VERSION ""

NS_ :

BS_:

BU_: XXX

BO_ 85 CID_AAKJTR: 8 XXX
 SG_ sig_rjgekf : 40|1@1+ (1,0) [0|1] "" XXX
 SG_ sig_xjcfym : 56|8@1+ (1,0) [0|255] "" XXX

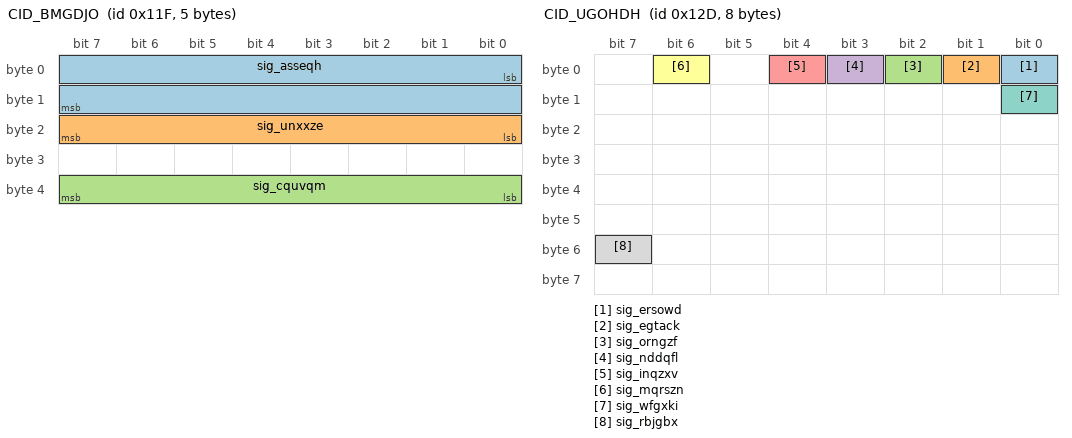
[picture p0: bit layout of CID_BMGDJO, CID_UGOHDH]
BO_ 287 CID_BMGDJO: 5 XXX
 SG_ sig_asseqh : 0|16@1- (0.1,0) [-450|450] "" XXX
 SG_ sig_unxxze : 16|8@1+ (4,0) [0|1020] "" XXX
 SG_ sig_cquvqm : 32|8@1+ (1,0) [0|255] "" XXX

BO_ 289 CID_QHFXJQ: 8 XXX
 SG_ sig_uldnjl : 0|12@1+ (1,0) [0|255] "" XXX

BO_ 301 CID_UGOHDH: 8 XXX
 SG_ sig_ersowd : 0|1@0+ (1,0) [0|1] "" XXX
 SG_ sig_egtack : 1|1@0+ (1,0) [0|1] "" XXX
 SG_ sig_orngzf : 2|1@0+ (1,0) [0|1] "" XXX
 SG_ sig_nddqfl : 3|1@0+ (1,0) [0|1] "" XXX
 SG_ sig_inqzxv : 4|1@0+ (1,0) [0|1] "" XXX
 SG_ sig_mqrszn : 6|1@0+ (1,0) [0|1] "" XXX
 SG_ sig_wfgxki : 8|1@0+ (1,0) [0|1] "" XXX
 SG_ sig_rbjgbx : 55|1@0+ (1,0) [0|1] "" XXX

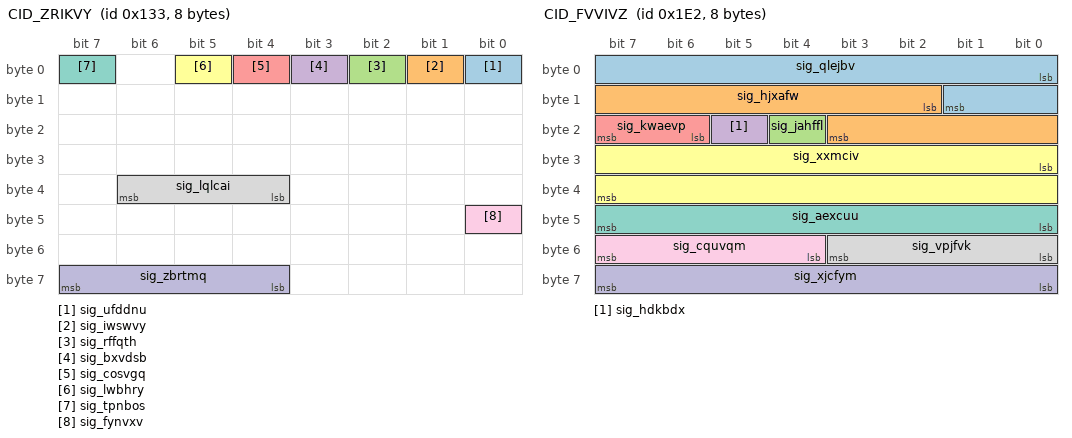
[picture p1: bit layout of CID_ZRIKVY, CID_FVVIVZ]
BO_ 307 CID_ZRIKVY: 8 XXX
 SG_ sig_ufddnu : 0|1@0+ (1,0) [0|1] "" XXX
 SG_ sig_iwswvy : 1|1@1+ (1,0) [0|1] "" XXX
 SG_ sig_rffqth : 2|1@1+ (1,0) [0|1] "" XXX
 SG_ sig_bxvdsb : 3|1@1+ (1,0) [0|1] "" XXX
 SG_ sig_cosvgq : 4|1@0+ (1,0) [0|1] "" XXX
 SG_ sig_lwbhry : 5|1@0+ (1,0) [0|1] "" XXX
 SG_ sig_tpnbos : 7|1@0+ (1,0) [0|1] "" XXX
 SG_ sig_lqlcai : 36|3@1+ (1,0) [0|7] "" XXX
 SG_ sig_fynvxv : 40|1@0+ (1,0) [0|1] "" XXX
 SG_ sig_zbrtmq : 63|4@0+ (1,0) [0|15] "" XXX

BO_ 482 CID_FVVIVZ: 8 XXX
 SG_ sig_qlejbv : 0|10@1- (0.01,0) [0|5] "" XXX
 SG_ sig_hjxafw : 10|10@1- (0.01,0) [-5|0] "" XXX
 SG_ sig_jahffl : 20|1@0+ (1,0) [0|1] "" XXX
 SG_ sig_hdkbdx : 21|1@0+ (1,0) [0|1] "" XXX
 SG_ sig_kwaevp : 22|2@1+ (1,0) [0|1] "" XXX
 SG_ sig_xxmciv : 24|16@1- (0.1,0) [-780|779.9] "" XXX
 SG_ sig_aexcuu : 47|8@0+ (1,0) [0|255] "" XXX
 SG_ sig_vpjfvk : 48|4@1+ (1,0) [0|15] "" XXX
 SG_ sig_cquvqm : 52|4@1+ (1,0) [0|15] "" XXX
 SG_ sig_xjcfym : 56|8@1+ (1,0) [0|255] "" XXX

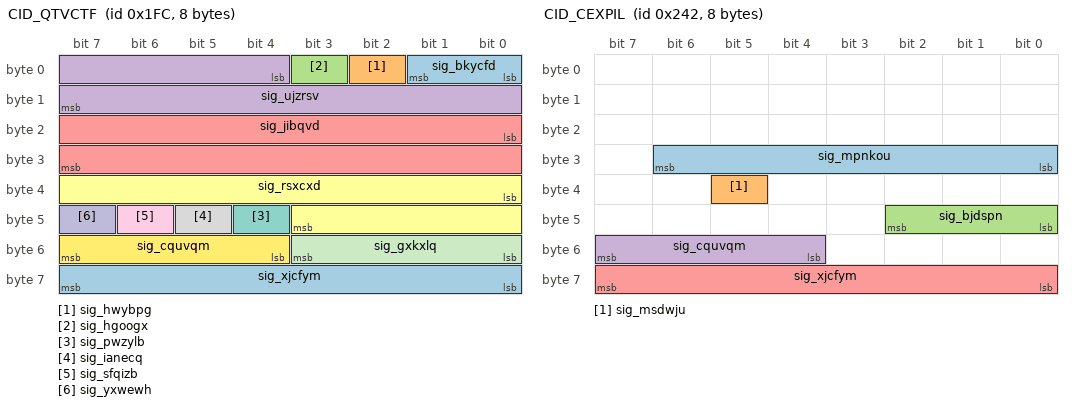
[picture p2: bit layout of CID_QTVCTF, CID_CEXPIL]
BO_ 508 CID_QTVCTF: 8 XXX
 SG_ sig_bkycfd : 0|2@1+ (1,0) [0|1] "" XXX
 SG_ sig_hwybpg : 2|1@1+ (1,0) [0|1] "" XXX
 SG_ sig_hgoogx : 3|1@0+ (1,0) [0|1] "" XXX
 SG_ sig_ujzrsv : 4|12@1- (1,0) [-2048|2047] "" XXX
 SG_ sig_jibqvd : 16|16@1- (0.1,0) [-780|779.9] "Deg" XXX
 SG_ sig_rsxcxd : 32|12@1- (1,0) [0|63] "" XXX
 SG_ sig_pwzylb : 44|1@0+ (1,0) [0|1] "" XXX
 SG_ sig_ianecq : 45|1@1+ (1,0) [0|255] "" XXX
 SG_ sig_sfqizb : 46|1@1+ (1,0) [0|1] "" XXX
 SG_ sig_yxwewh : 47|1@0+ (1,0) [0|3] "" XXX
 SG_ sig_gxkxlq : 48|4@1+ (1,0) [0|15] "" XXX
 SG_ sig_cquvqm : 52|4@1+ (1,0) [0|15] "" XXX
 SG_ sig_xjcfym : 56|8@1+ (1,0) [0|255] "" XXX

BO_ 578 CID_CEXPIL: 8 XXX
 SG_ sig_mpnkou : 30|7@0+ (1,0) [0|127] "" XXX
 SG_ sig_msdwju : 37|1@0+ (1,0) [0|1] "" XXX
 SG_ sig_bjdspn : 40|3@1+ (1,0) [0|7] "" XXX
 SG_ sig_cquvqm : 55|4@0+ (1,0) [0|15] "" XXX
 SG_ sig_xjcfym : 56|8@1+ (1,0) [0|255] "" XXX

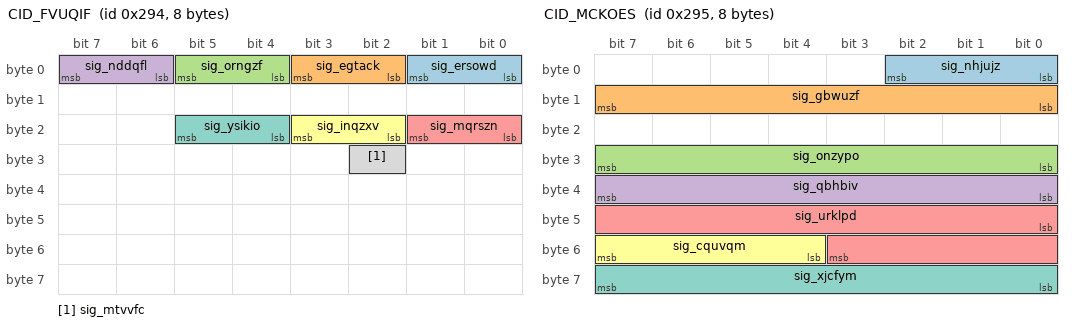
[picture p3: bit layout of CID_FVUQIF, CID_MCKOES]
BO_ 660 CID_FVUQIF: 8 XXX
 SG_ sig_ersowd : 1|2@0+ (1,0) [0|3] "" XXX
 SG_ sig_egtack : 3|2@0+ (1,0) [0|3] "" XXX
 SG_ sig_orngzf : 5|2@0+ (1,0) [0|3] "" XXX
 SG_ sig_nddqfl : 7|2@0+ (1,0) [0|3] "" XXX
 SG_ sig_mqrszn : 17|2@0+ (1,0) [0|3] "" XXX
 SG_ sig_inqzxv : 19|2@0+ (1,0) [0|3] "" XXX
 SG_ sig_ysikio : 21|2@0+ (1,0) [0|3] "" XXX
 SG_ sig_mtvvfc : 26|1@0+ (1,0) [0|1] "" XXX

BO_ 661 CID_MCKOES: 8 XXX
 SG_ sig_nhjujz : 2|3@0+ (1,0) [0|7] "" XXX
 SG_ sig_gbwuzf : 15|8@0+ (1,0) [0|255] "" XXX
 SG_ sig_onzypo : 31|8@0+ (1,0) [0|255] "" XXX
 SG_ sig_qbhbiv : 32|8@1+ (1,0) [0|255] "" XXX
 SG_ sig_urklpd : 40|12@1+ (1,0) [0|255] "" XXX
 SG_ sig_cquvqm : 52|4@1+ (1,0) [0|15] "" XXX
 SG_ sig_xjcfym : 63|8@0+ (1,0) [0|255] "" XXX

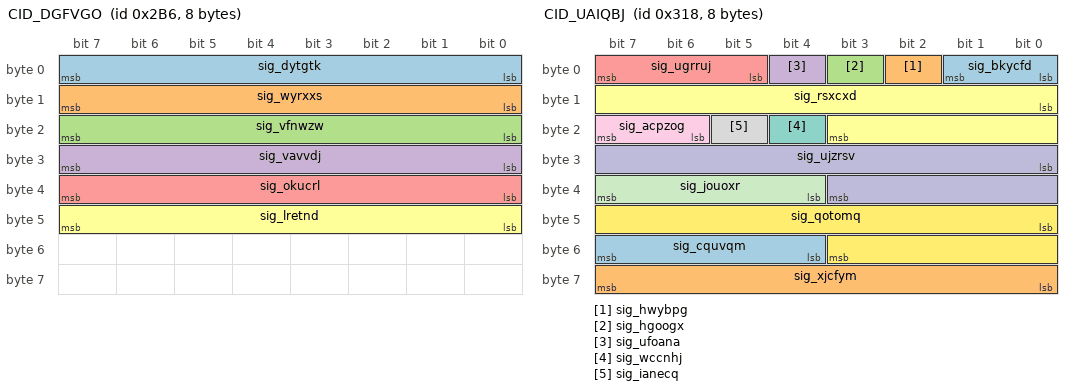
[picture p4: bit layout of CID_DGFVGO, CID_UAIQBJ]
BO_ 694 CID_DGFVGO: 8 XXX
 SG_ sig_dytgtk : 7|8@0+ (1,0) [0|255] "" XXX
 SG_ sig_wyrxxs : 15|8@0+ (1,0) [0|255] "" XXX
 SG_ sig_vfnwzw : 23|8@0+ (1,0) [0|255] "" XXX
 SG_ sig_vavvdj : 31|8@0+ (1,0) [0|255] "" XXX
 SG_ sig_okucrl : 39|8@0+ (1,0) [0|255] "" XXX
 SG_ sig_lretnd : 47|8@0+ (1,0) [0|255] "" XXX

BO_ 790 CID_OANJWA: 8 XXX
 SG_ sig_tidylo : 3|4@0+ (1,0) [0|1] "" XXX
 SG_ sig_bzvjkw : 4|2@1+ (1,0) [0|3] "" XXX
 SG_ sig_frfqzv : 6|2@1+ (1,0) [0|3] "" XXX
 SG_ sig_grirwu : 8|2@1+ (1,0) [0|3] "" XXX
 SG_ sig_tpqchs : 10|1@1+ (1,0) [0|1] "" XXX
 SG_ sig_fterep : 11|4@1+ (1,0) [0|1] "" XXX
 SG_ sig_aupjpc : 15|1@0+ (1,0) [0|1] "" XXX
 SG_ sig_xxmciv : 16|11@1- (1,0) [-1024|1023] "" XXX
 SG_ sig_jahffl : 27|1@1+ (1,0) [0|1] "" XXX
 SG_ sig_hdkbdx : 28|1@1+ (1,0) [0|3] "" XXX
 SG_ sig_ttxarj : 29|1@0+ (1,0) [0|1] "" XXX
 SG_ sig_nyqzlm : 30|1@0+ (1,0) [0|1] "" XXX
 SG_ sig_sapher : 31|1@0+ (1,0) [0|1] "" XXX
 SG_ sig_stewol : 32|2@1+ (1,0) [0|3] "" XXX
 SG_ sig_cqnbjs : 34|2@1+ (1,0) [0|3] "" XXX
 SG_ sig_ridjbe : 36|4@1+ (1,0) [0|3] "" XXX
 SG_ sig_pscbla : 40|8@1+ (5,-5) [-5|1270] "" XXX
 SG_ sig_ghntec : 49|2@0+ (1,0) [0|3] "" XXX
 SG_ sig_qhdjrz : 51|2@0+ (1,0) [0|3] "" XXX
 SG_ sig_cquvqm : 52|4@1+ (1,0) [0|15] "" XXX
 SG_ sig_xjcfym : 56|8@1+ (1,0) [0|15] "" XXX

BO_ 792 CID_UAIQBJ: 8 XXX
 SG_ sig_bkycfd : 0|2@1+ (1,0) [0|1] "" XXX
 SG_ sig_hwybpg : 2|1@1+ (1,0) [0|1] "" XXX
 SG_ sig_hgoogx : 3|1@1+ (1,0) [0|1] "" XXX
 SG_ sig_ufoana : 4|1@1+ (1,0) [0|1] "" XXX
 SG_ sig_ugrruj : 5|3@1+ (1,0) [0|1] "" XXX
 SG_ sig_rsxcxd : 8|12@1- (1,0) [-2048|2047] "" XXX
 SG_ sig_wccnhj : 20|1@1+ (1,0) [0|1] "" XXX
 SG_ sig_ianecq : 21|1@1+ (1,0) [0|1] "" XXX
 SG_ sig_acpzog : 22|2@1+ (1,0) [0|15] "" XXX
 SG_ sig_ujzrsv : 24|12@1- (1,0) [-2048|2047] "" XXX
 SG_ sig_jouoxr : 36|4@1+ (1,0) [0|15] "" XXX
 SG_ sig_qotomq : 40|12@1+ (1,0) [0|4095] "" XXX
 SG_ sig_cquvqm : 52|4@1+ (1,0) [0|15] "" XXX
 SG_ sig_xjcfym : 56|8@1+ (1,0) [0|255] "" XXX

BO_ 813 CID_LMYPOB: 8 XXX
 SG_ sig_axakla : 0|9@1+ (0.5,0) [0|255.5] "" XXX
 SG_ sig_eysfbr : 9|1@1+ (1,0) [0|1] "" XXX
 SG_ sig_occdnv : 10|3@1+ (1,0) [0|7] "" XXX
 SG_ sig_cxglbg : 13|3@1+ (1,0) [0|7] "" XXX
 SG_ sig_qledps : 16|1@1+ (1,0) [0|1] "" XXX
 SG_ sig_kjbpzp : 17|1@1+ (1,0) [0|1] "" XXX
 SG_ sig_hgoogx : 18|1@1+ (1,0) [0|1] "" XXX
 SG_ sig_zggron : 19|3@1+ (1,0) [0|1] "" XXX
 SG_ sig_kfsadc : 22|1@0+ (1,0) [0|1] "" XXX
 SG_ sig_xplnuv : 23|1@0+ (1,0) [0|1] "" XXX
 SG_ sig_grirwu : 24|1@1+ (1,0) [0|1] "" XXX
 SG_ sig_tphtqh : 25|7@1+ (1,0) [0|127] "" XXX
 SG_ sig_qtgocq : 32|4@1+ (1,0) [0|15] "" XXX
 SG_ sig_wpgtxb : 36|12@1+ (1,0) [0|4095] "" XXX
 SG_ sig_cquvqm : 48|4@1+ (1,0) [0|15] "" XXX
 SG_ sig_jeqena : 55|4@0+ (1,0) [0|15] "" XXX
 SG_ sig_xjcfym : 56|8@1+ (1,0) [0|255] "" XXX

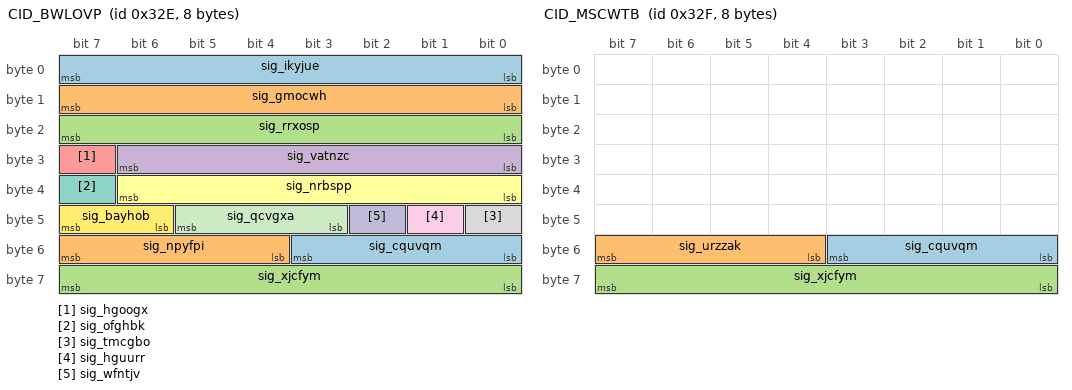
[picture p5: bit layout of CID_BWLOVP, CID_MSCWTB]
BO_ 814 CID_BWLOVP: 8 XXX
 SG_ sig_ikyjue : 0|8@1+ (0.05,-5) [-100|155] "" XXX
 SG_ sig_gmocwh : 8|8@1+ (0.05,-5) [0|1.26] "" XXX
 SG_ sig_rrxosp : 16|8@1+ (0.05,-5) [0|1.26] "" XXX
 SG_ sig_vatnzc : 24|7@1+ (0.2,0) [0|12.7] "" XXX
 SG_ sig_hgoogx : 31|1@0+ (1,0) [0|1] "" XXX
 SG_ sig_nrbspp : 32|7@1+ (0.2,-16) [0|12.7] "" XXX
 SG_ sig_ofghbk : 39|1@0+ (1,0) [0|1] "" XXX
 SG_ sig_tmcgbo : 40|1@0+ (1,0) [0|1] "" XXX
 SG_ sig_hguurr : 41|1@0+ (1,0) [0|1] "" XXX
 SG_ sig_wfntjv : 42|1@1+ (1,0) [0|3] "" XXX
 SG_ sig_qcvgxa : 45|3@0+ (1,0) [0|1] "" XXX
 SG_ sig_bayhob : 46|2@1+ (1,0) [0|3] "" XXX
 SG_ sig_cquvqm : 48|4@1+ (1,0) [0|15] "" XXX
 SG_ sig_npyfpi : 55|4@0+ (1,0) [0|15] "" XXX
 SG_ sig_xjcfym : 56|8@1+ (1,0) [0|255] "" XXX

BO_ 815 CID_MSCWTB: 8 XXX
 SG_ sig_cquvqm : 48|4@1+ (1,0) [0|15] "" XXX
 SG_ sig_urzzak : 55|4@0+ (1,0) [0|15] "" XXX
 SG_ sig_xjcfym : 56|8@1+ (1,0) [0|255] "" XXX

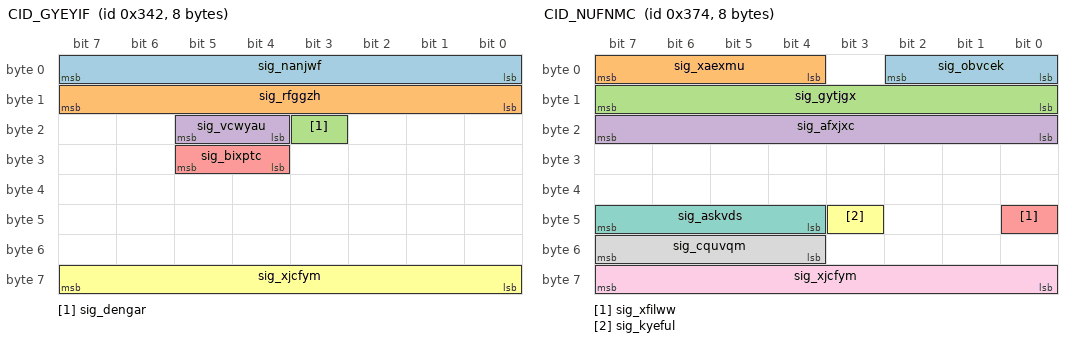
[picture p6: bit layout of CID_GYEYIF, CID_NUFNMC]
BO_ 834 CID_GYEYIF: 8 XXX
 SG_ sig_nanjwf : 0|8@1+ (0.01,0) [0|2.55] "" XXX
 SG_ sig_rfggzh : 8|8@1+ (0.01,0) [0|2.55] "" XXX
 SG_ sig_dengar : 19|1@1+ (1,0) [0|1] "" XXX
 SG_ sig_vcwyau : 20|2@1+ (1,0) [0|255] "" XXX
 SG_ sig_bixptc : 28|2@1+ (1,0) [0|1] "" XXX
 SG_ sig_xjcfym : 56|8@1+ (1,0) [0|255] "" XXX

BO_ 884 CID_NUFNMC: 8 MRR
 SG_ sig_obvcek : 2|3@0+ (1,0) [0|3] "" MRR
 SG_ sig_xaexmu : 7|4@0+ (1,0) [0|15] "" MRR
 SG_ sig_gytjgx : 15|8@0+ (0.1,-12) [0|255] "" MRR
 SG_ sig_afxjxc : 23|8@0+ (1,-100) [0|255] "" MRR
 SG_ sig_xfilww : 40|1@0+ (1,0) [0|3] "" MRR
 SG_ sig_kyeful : 43|1@0+ (1,0) [0|1] "" XXX
 SG_ sig_askvds : 44|4@1+ (1,0) [0|15] "" XXX
 SG_ sig_cquvqm : 52|4@1+ (1,0) [0|15] "" MRR
 SG_ sig_xjcfym : 56|8@1+ (1,0) [0|255] "" MRR

BO_ 944 CID_QNJDWB: 8 XXX
 SG_ sig_kpflgl : 1|2@0+ (1,0) [0|3] "" XXX
 SG_ sig_bzzyzt : 2|1@0+ (1,0) [0|1] "" XXX
 SG_ sig_iapwtw : 4|2@0+ (1,0) [0|3] "" XXX
 SG_ sig_xuwcxo : 5|1@0+ (1,0) [0|1] "" XXX
 SG_ sig_ftneny : 6|1@0+ (1,0) [0|1] "" XXX
 SG_ sig_gvbklm : 7|1@0+ (1,0) [0|1] "" XXX
 SG_ sig_ekacrz : 8|1@0+ (1,0) [0|1] "" XXX
 SG_ sig_yjvvac : 11|3@0+ (1,0) [0|7] "" XXX
 SG_ sig_aycwqi : 12|1@0+ (1,0) [0|1] "" XXX
 SG_ sig_udklzz : 14|2@0+ (1,0) [0|3] "" XXX
 SG_ sig_ydspin : 15|1@0+ (1,0) [0|1] "" XXX
 SG_ sig_jibbej : 16|1@0+ (1,0) [0|1] "" XXX
 SG_ sig_lzzdjo : 18|2@0+ (1,0) [0|3] "" XXX
 SG_ sig_uctvkf : 19|1@0+ (1,0) [0|1] "" XXX
 SG_ sig_apzibg : 23|4@0+ (1,0) [0|15] "" XXX
 SG_ sig_elxjpx : 24|28@1+ (1,0) [0|268435455] "" XXX
 SG_ sig_cquvqm : 52|4@1+ (1,0) [0|15] "" XXX
 SG_ sig_xjcfym : 56|8@1+ (1,0) [0|255] "" XXX

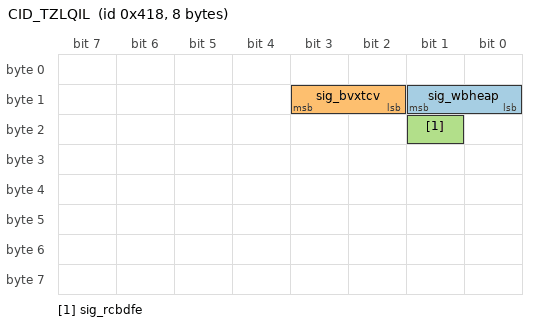
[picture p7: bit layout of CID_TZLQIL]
BO_ 1048 CID_TZLQIL: 8 XXX
 SG_ sig_wbheap : 9|2@0+ (1,0) [0|1] "" XXX
 SG_ sig_bvxtcv : 11|2@0+ (1,0) [0|1] "" XXX
 SG_ sig_rcbdfe : 17|1@0+ (1,0) [0|1] "" XXX

VAL_ 578 sig_bjdspn 4 "D" 2 "R" 3 "N" 1 "P";
VAL_ 790 sig_tidylo 11 "AutoFullBeamActive" 2 "AutoFullBeamInactive";
VAL_ 790 sig_bzvjkw 0 "GRAY" 1 "GREEN" 2 "YELLOW" 3 "RED";
VAL_ 790 sig_frfqzv 3 "ALARM_AND_LKA" 2 "LKA" 1 "ALARM" 0 "DISABLE";
VAL_ 790 sig_cqnbjs 0 "GRAY" 1 "GREEN" 2 "YELLOW" 3 "RED";
VAL_ 790 sig_ghntec 0 "VIBRATION" 1 "AUDIO" 2 "AUDIO_AND_VIBRATION";
VAL_ 792 sig_bkycfd 0 "NotReady" 1 "Ready" 2 "Active" 3 "TemporaryFail";
VAL_ 813 sig_occdnv 4 "4BAR" 3 "3BAR" 2 "2BAR" 1 "1BAR";
VAL_ 813 sig_zggron 0 "OFF" 2 "ACC_ON" 3 "ACC_ACTIVE" 5 "FORCE_ACCEL" 7 "ERROR";
VAL_ 813 sig_tphtqh 36 "ACC_ERROR" 22 "OVERRIDE" 12 "ENGAGE" 8 "DISENGAGE" 20 "ACC_ON" 32 "ACC_OFF" 48 "CHECK_GEAR_D" 16 "FORCE_ACCEL" 0 "NONE";
VAL_ 814 sig_qcvgxa 0 "Off" 1 "Passive" 2 "StandBy" 3 "ActiveControl" 4 "BrakeOnly" 5 "Override" 6 "Standstill" 7 "Failure";
VAL_ 814 sig_bayhob 0 "Softoff" 1 "Fastoff" 2 "Immediateoff" 3 "Initial";
VAL_ 834 sig_vcwyau 2 "SPORT" 1 "ECO" 0 "SNOW";
VAL_ 834 sig_bixptc 3 "HEV" 2 "FORCE_EV" 1 "EV";
VAL_ 944 sig_iapwtw 0 "NOTPRESSED" 1 "DOWN_SETSPEED" 3 "UP_RESETSPEED";
